# STM32H725ZGT7 register map
File version: 1.0
Registers are 32-bit, access not given, reset 0x0 unless marked. A register's access mark holds for its fields unless they carry their own. Offsets are from the block's base; [hi:lo] are bit positions; {n}, {i} and the like mark numbered series; 'fields as' and 'values as' point back to an identical list.

## OCTOSPI1
Base 0x52005000
Same registers: OCTOSPI2 0x5200A000
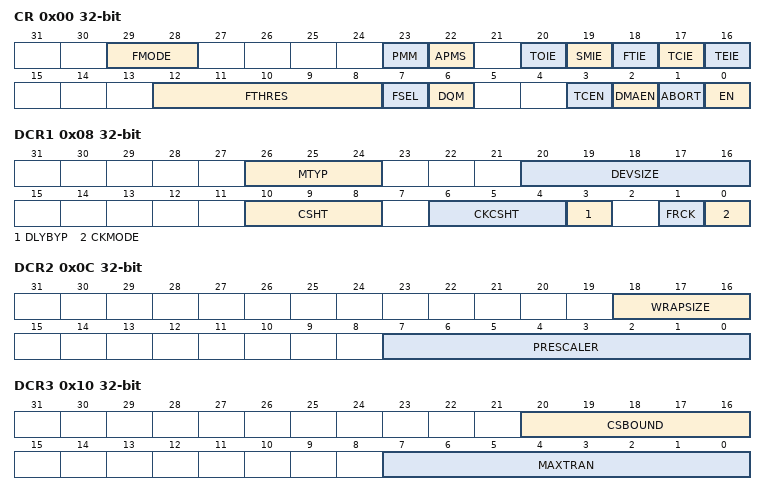
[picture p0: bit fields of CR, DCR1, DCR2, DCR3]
0x00 CR
  [29:28] FMODE, [23] PMM, [22] APMS, [20] TOIE, [19] SMIE, [18] FTIE, [17] TCIE, [16] TEIE, [12:8] FTHRES, [7] FSEL, [6] DQM, [3] TCEN, [2] DMAEN, [1] ABORT, [0] EN
0x08 DCR1
  [26:24] MTYP, [20:16] DEVSIZE, [10:8] CSHT, [6:4] CKCSHT, [3] DLYBYP, [1] FRCK, [0] CKMODE
0x0C DCR2
  [18:16] WRAPSIZE, [7:0] PRESCALER
0x10 DCR3
  [20:16] CSBOUND, [7:0] MAXTRAN
0x14 DCR4
  [31:0] REFRESH
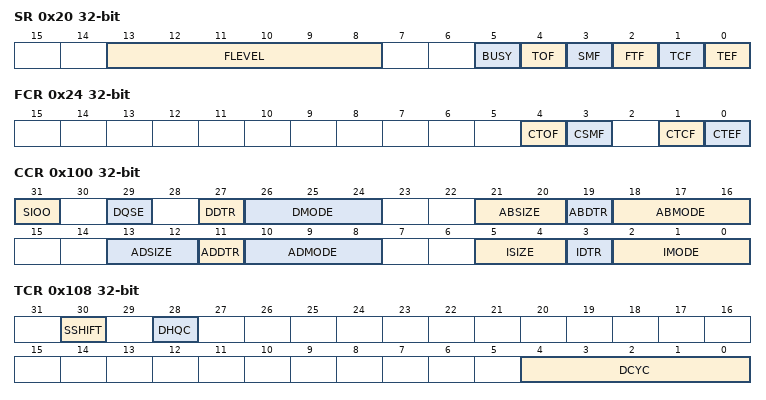
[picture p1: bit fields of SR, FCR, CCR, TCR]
0x20 SR
  [13:8] FLEVEL, [5] BUSY, [4] TOF, [3] SMF, [2] FTF, [1] TCF, [0] TEF
0x24 FCR
  [4] CTOF, [3] CSMF, [1] CTCF, [0] CTEF
0x40 DLR
  [31:0] DL
0x48 AR
  [31:0] ADDRESS
0x50 DR
  [31:0] DATA
0x80 PSMKR
  [31:0] MASK
0x88 PSMAR
  [31:0] MATCH
0x90 PIR
  [15:0] INTERVAL
0x100 CCR
  [31] SIOO, [29] DQSE, [27] DDTR, [26:24] DMODE, [21:20] ABSIZE, [19] ABDTR, [18:16] ABMODE, [13:12] ADSIZE, [11] ADDTR, [10:8] ADMODE, [5:4] ISIZE, [3] IDTR, [2:0] IMODE
0x108 TCR
  [30] SSHIFT, [28] DHQC, [4:0] DCYC
0x110 IR
  [31:0] INSTRUCTION
0x120 ABR
  [31:0] ALTERNATE
0x130 LPTR
  [15:0] TIMEOUT
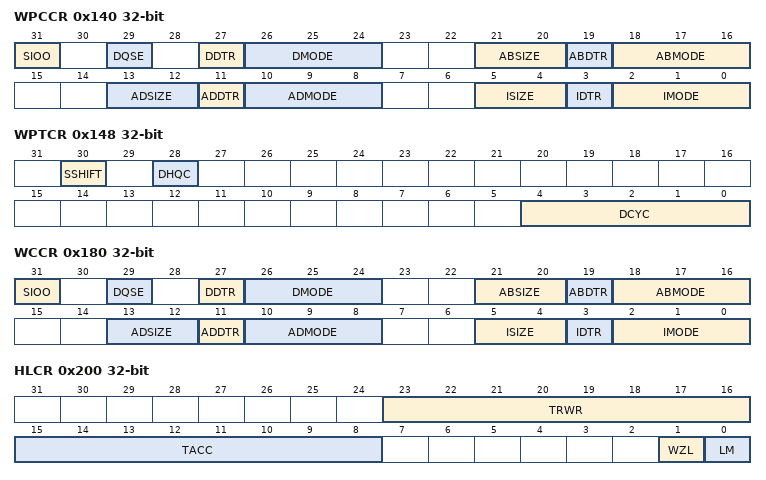
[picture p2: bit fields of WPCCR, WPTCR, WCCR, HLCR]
0x140 WPCCR
  fields as CCR
0x148 WPTCR
  [30] SSHIFT, [28] DHQC, [4:0] DCYC
0x150 WPIR
  [31:0] INSTRUCTION
0x160 WPABR
  [31:0] ALTERNATE
0x180 WCCR
  fields as CCR
0x188 WTCR
  [4:0] DCYC
0x190 WIR
  [31:0] INSTRUCTION
0x1A0 WABR
  [31:0] ALTERNATE
0x200 HLCR
  [23:16] TRWR, [15:8] TACC, [1] WZL, [0] LM
0x3EC HWCFGR
0x3F0 VER
  [7:0] VER
0x3F4 ID
0x3F8 MID

## OCTOSPIM
Base 0x5200B400
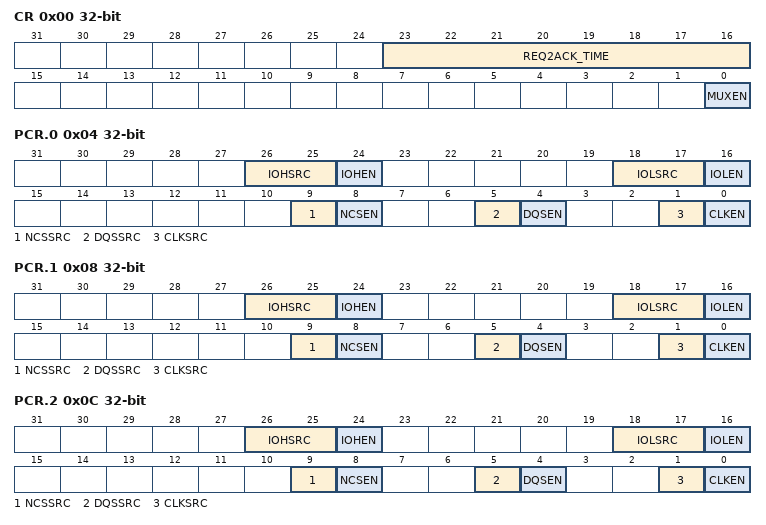
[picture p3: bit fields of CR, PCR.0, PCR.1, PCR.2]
0x00 CR
  [23:16] REQ2ACK_TIME, [0] MUXEN
0x04 PCR.0
  [26:25] IOHSRC, [24] IOHEN, [18:17] IOLSRC, [16] IOLEN, [9] NCSSRC, [8] NCSEN, [5] DQSSRC, [4] DQSEN, [1] CLKSRC, [0] CLKEN
0x08 PCR.1
  fields as PCR.0
0x0C PCR.2
  fields as PCR.0

## EXTI
Base 0x58000000
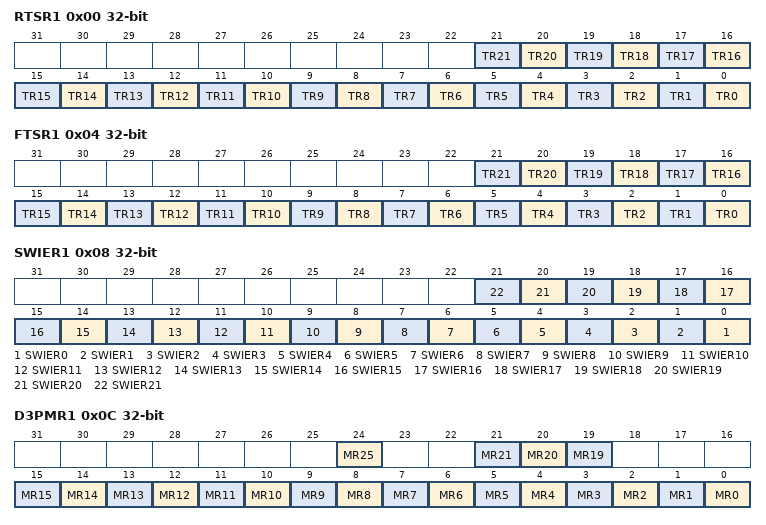
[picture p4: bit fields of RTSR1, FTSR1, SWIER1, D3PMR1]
0x00 RTSR1
  [n] TR{n} (n=0..21)
0x04 FTSR1
  [n] TR{n} (n=0..21)
0x08 SWIER1
  [n] SWIER{n} (n=0..21)
0x0C D3PMR1
  [24] MR25, [21] MR21, [20] MR20, [19] MR19, [n] MR{n} (n=0..15)
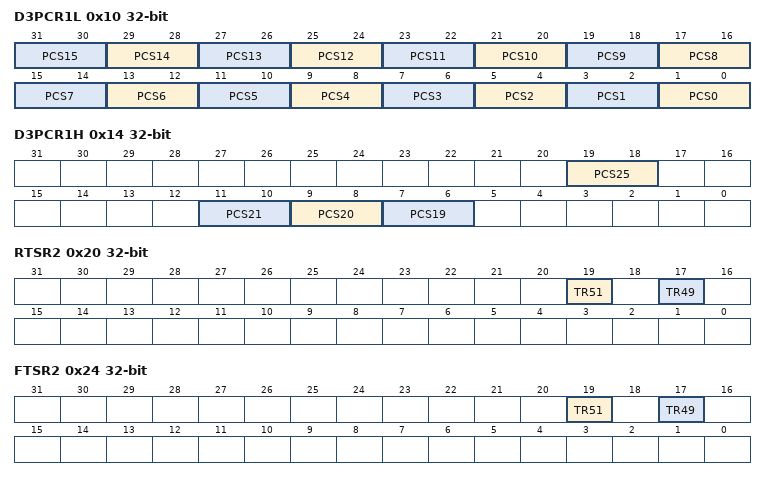
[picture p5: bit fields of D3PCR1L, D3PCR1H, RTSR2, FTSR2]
0x10 D3PCR1L
  [2n+1:2n] PCS{n} (n=0..15)
0x14 D3PCR1H
  [19:18] PCS25, [11:10] PCS21, [9:8] PCS20, [7:6] PCS19
0x20 RTSR2
  [19] TR51, [17] TR49
0x24 FTSR2
  [19] TR51, [17] TR49
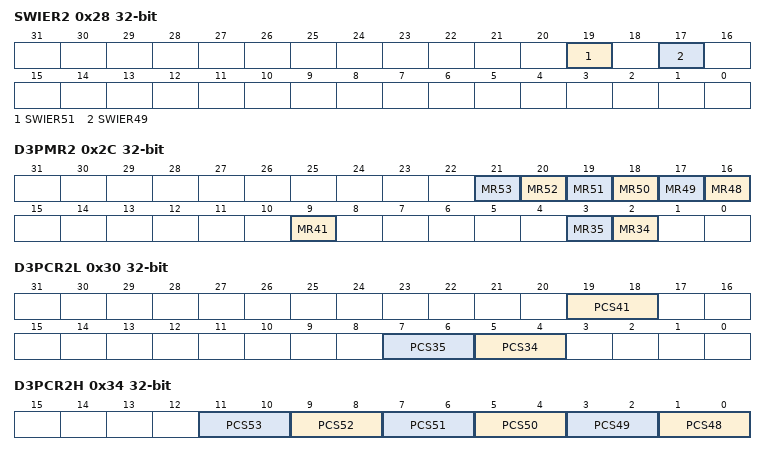
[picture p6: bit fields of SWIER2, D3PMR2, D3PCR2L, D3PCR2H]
0x28 SWIER2
  [19] SWIER51, [17] SWIER49
0x2C D3PMR2
  [n-32] MR{n} (n=48..53), [9] MR41, [3] MR35, [2] MR34
0x30 D3PCR2L
  [19:18] PCS41, [7:6] PCS35, [5:4] PCS34
0x34 D3PCR2H
  [2n-95:2n-96] PCS{n} (n=48..53)
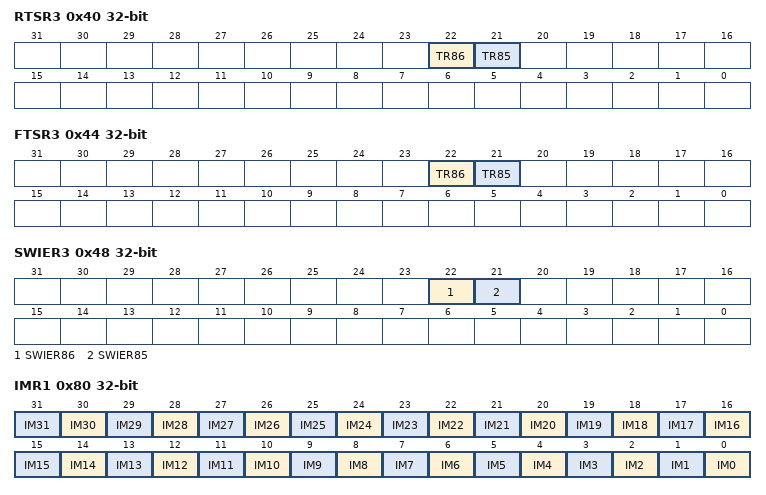
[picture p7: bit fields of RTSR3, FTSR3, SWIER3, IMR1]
0x40 RTSR3
  [22] TR86, [21] TR85
0x44 FTSR3
  [22] TR86, [21] TR85
0x48 SWIER3
  [22] SWIER86, [21] SWIER85
0x4C D3PMR3
  [24] MR88
0x50 D3PCR3L
0x54 D3PCR3H
  [17:16] PCS88
0x80 IMR1
  [n] IM{n} (n=0..31)
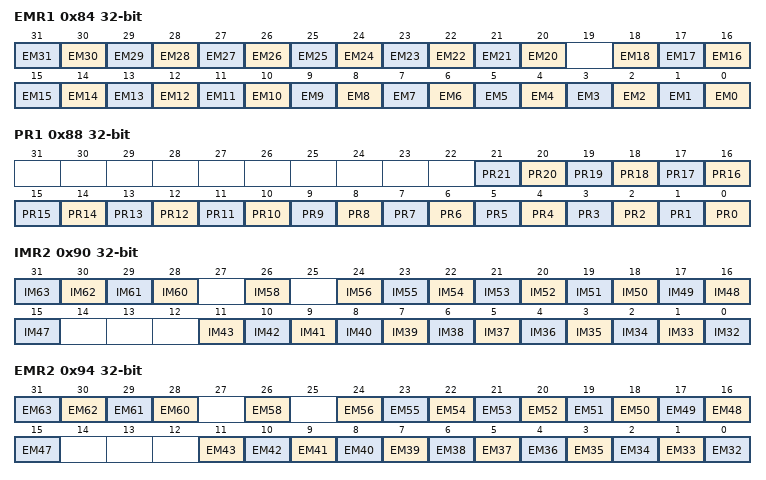
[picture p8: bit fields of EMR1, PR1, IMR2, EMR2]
0x84 EMR1
  [n] EM{n} (n=20..31), [n] EM{n} (n=0..18)
0x88 PR1
  [n] PR{n} (n=0..21)
0x90 IMR2
  [n-32] IM{n} (n=60..63), [26] IM58, [n-32] IM{n} (n=47..56), [n-32] IM{n} (n=32..43)
0x94 EMR2
  [n-32] EM{n} (n=60..63), [26] EM58, [n-32] EM{n} (n=47..56), [n-32] EM{n} (n=32..43)
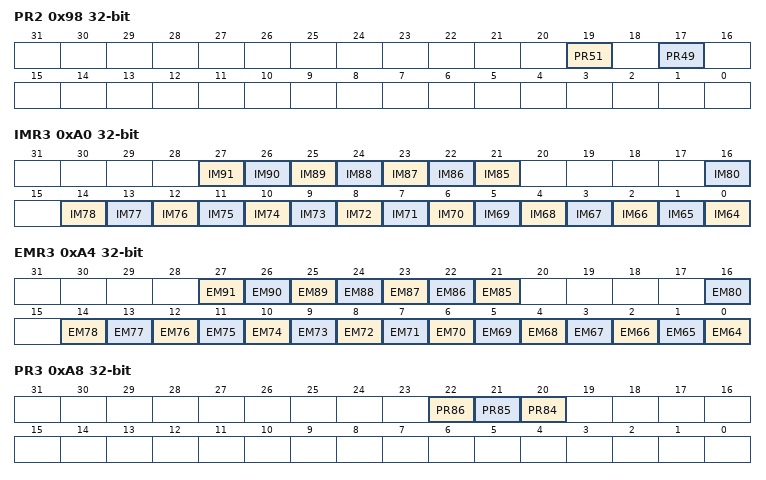
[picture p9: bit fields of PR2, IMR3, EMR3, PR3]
0x98 PR2
  [19] PR51, [17] PR49
0xA0 IMR3
  [n-64] IM{n} (n=85..91), [16] IM80, [n-64] IM{n} (n=64..78)
0xA4 EMR3
  [n-64] EM{n} (n=85..91), [16] EM80, [n-64] EM{n} (n=64..78)
0xA8 PR3
  [22] PR86, [21] PR85, [20] PR84

## EXTI_D1
Base 0x58000080
Same registers: EXTI_D2 0x580000C0
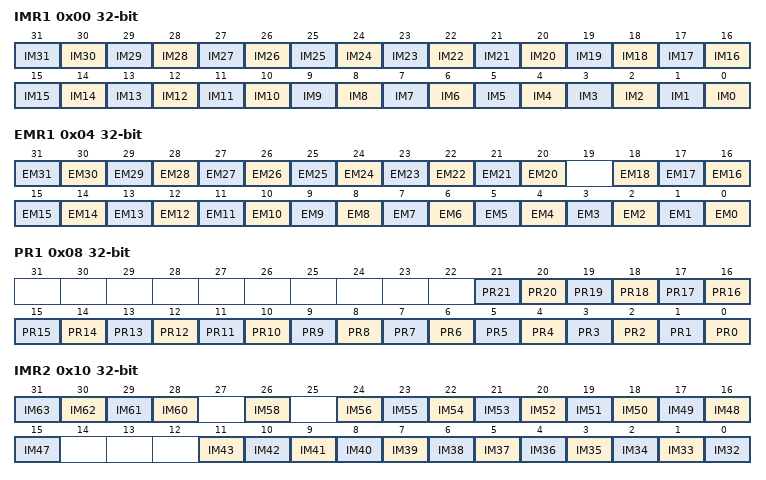
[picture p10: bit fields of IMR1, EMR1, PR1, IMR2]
0x00 IMR1
  [n] IM{n} (n=0..31)
0x04 EMR1
  [n] EM{n} (n=20..31), [n] EM{n} (n=0..18)
0x08 PR1
  [n] PR{n} (n=0..21)
0x10 IMR2
  [n-32] IM{n} (n=60..63), [26] IM58, [n-32] IM{n} (n=47..56), [n-32] IM{n} (n=32..43)
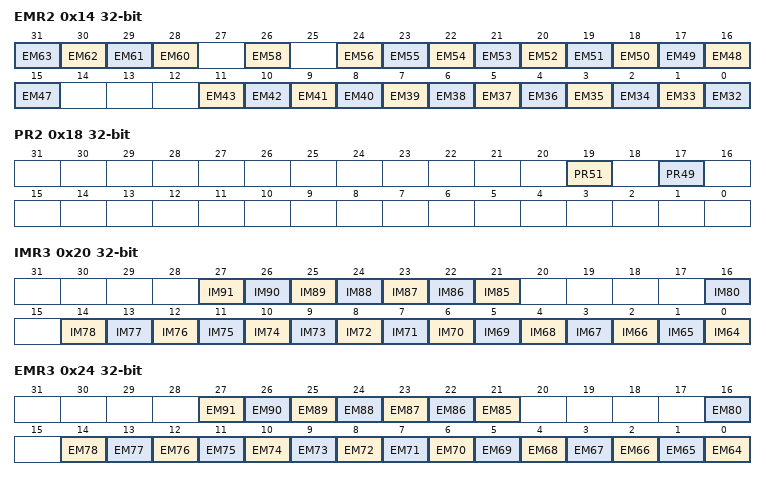
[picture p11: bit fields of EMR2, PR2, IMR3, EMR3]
0x14 EMR2
  [n-32] EM{n} (n=60..63), [26] EM58, [n-32] EM{n} (n=47..56), [n-32] EM{n} (n=32..43)
0x18 PR2
  [19] PR51, [17] PR49
0x20 IMR3
  [n-64] IM{n} (n=85..91), [16] IM80, [n-64] IM{n} (n=64..78)
0x24 EMR3
  [n-64] EM{n} (n=85..91), [16] EM80, [n-64] EM{n} (n=64..78)
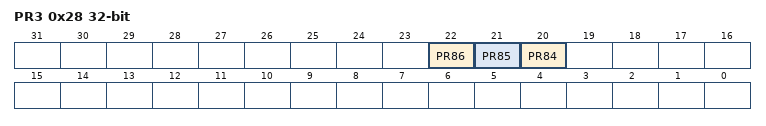
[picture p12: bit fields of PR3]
0x28 PR3
  [22] PR86, [21] PR85, [20] PR84

## SYSCFG
Base 0x58000400
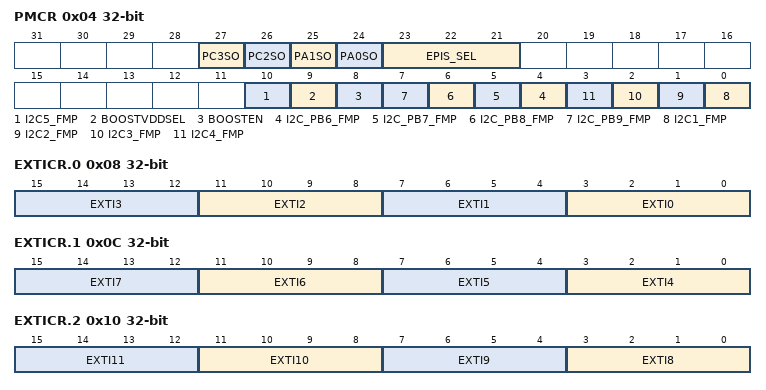
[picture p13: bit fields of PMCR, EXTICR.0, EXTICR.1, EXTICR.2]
0x04 PMCR
  [27] PC3SO, [26] PC2SO, [25] PA1SO, [24] PA0SO, [23:21] EPIS_SEL, [10] I2C5_FMP, [9] BOOSTVDDSEL, [8] BOOSTEN, [n-2] I2C_PB{n}_FMP (n=6..9), [n-1] I2C{n}_FMP (n=1..4)
0x08 EXTICR.0
  [4n+3:4n] EXTI{n} (n=0..3)
0x0C EXTICR.1
  [4n-13:4n-16] EXTI{n} (n=4..7)
0x10 EXTICR.2
  [4n-29:4n-32] EXTI{n} (n=8..11)
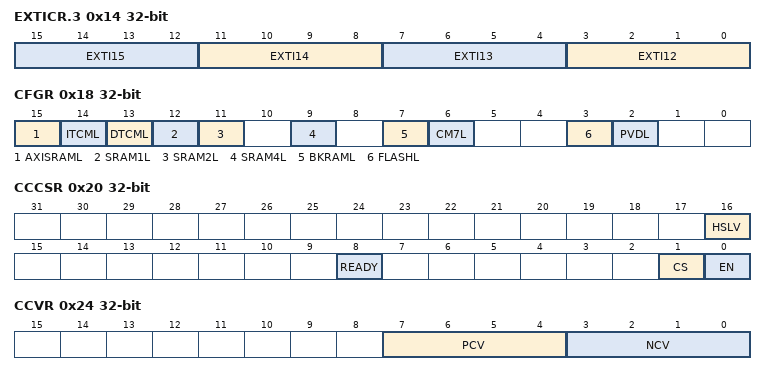
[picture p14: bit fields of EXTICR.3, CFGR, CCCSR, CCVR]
0x14 EXTICR.3
  [4n-45:4n-48] EXTI{n} (n=12..15)
0x18 CFGR
  [15] AXISRAML, [14] ITCML, [13] DTCML, [12] SRAM1L, [11] SRAM2L, [9] SRAM4L, [7] BKRAML, [6] CM7L, [3] FLASHL, [2] PVDL
0x20 CCCSR
  [16] HSLV, [8] READY, [1] CS, [0] EN
0x24 CCVR
  [7:4] PCV, [3:0] NCV
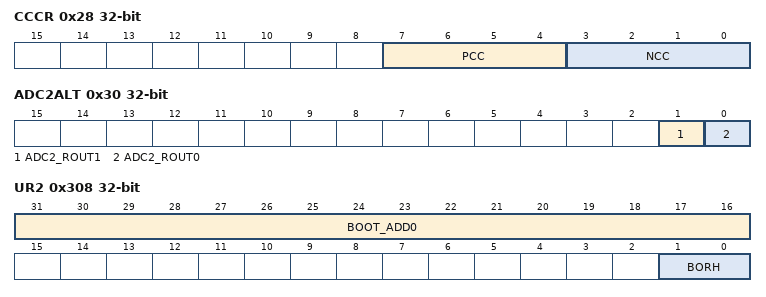
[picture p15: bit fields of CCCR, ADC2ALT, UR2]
0x28 CCCR
  [7:4] PCC, [3:0] NCC
0x30 ADC2ALT
  [1] ADC2_ROUT1, [0] ADC2_ROUT0
0x124 PKGR
  [3:0] PKG
0x300 UR0
  [23:16] RDP
0x304 UR1
0x308 UR2
  [31:16] BOOT_ADD0, [1:0] BORH
0x30C UR3
  [15:0] BOOT_ADD1
0x310 UR4
  [16] MEPAD_BANK1
0x314 UR5
  [23:16] WRPN_BANK1, [0] MESAD_BANK1
0x318 UR6
  [27:16] PAEND_BANK1, [11:0] PABEG_BANK1
0x31C UR7
  [27:16] SAEND_BANK1, [11:0] SABEG_BANK1
0x32C UR11
  [16] IWDG1M
0x330 UR12
  [16] SECURE
0x334 UR13
  [16] D1SBRST, [1:0] SDRS
0x338 UR14
  [0] D1STPRST
0x33C UR15
  [16] FZIWDGSTB
0x340 UR16
  [16] PKP, [0] FZIWDGSTP
0x344 UR17
  [17:16] TCM_AXI_CFG, [0] IOHSLV
0x348 UR18
  [0] CPU_FREQ_BOOST
